# PIC32CK2051GC01064 register map
Vendor: Microchip Technology; Series: PIC32CKGC01; File version: 0
CPU: CM33 r0p0, little endian, MPU, FPU, DSP, 3 interrupt priority bits, 158 interrupts
Registers are 32-bit, read-write, reset 0x0 unless marked. A register's access mark holds for its fields unless they carry their own. Offsets are from the block's base; [hi:lo] are bit positions; {n}, {i} and the like mark numbered series.

## CoreDebug — Debug Control Block
Base 0xE000EDF0
0x00 DHCSR — Debug Halting Control and Status Register
  [26] S_RESTART_ST ro — Restart sticky status
  [25] S_RESET_ST ro — Reset sticky status
  [24] S_RETIRE_ST ro — Retire sticky status
  [23] S_FPD ro — Floating-point registers Debuggable
  [22] S_SUIDE ro — Secure unprivileged-only halting debug enabled
  [21] S_NSUIDE ro — Non-secure unprivileged-only haltingdebug enabled
  [20] S_SDE ro — Secure debug enabled
  [19] S_LOCKUP ro — Lockup status
  [18] S_SLEEP ro — Sleeping status
  [17] S_HALT ro — Halted status
  [16] S_REGRDY ro — Register ready status
  [31:16] DBGKEY wo — Debug key, must write 0xA05F to enable writes
  [6] C_PMOV — Halt on PMU overflow contro
  [5] C_SNAPSTALL — Snap stall control
  [3] C_MASKINTS — Mask PendSV, SysTick and external configurable interrupts
  [2] C_STEP — Enable single step
  [1] C_HALT — Halt processor
  [0] C_DEBUGEN — Enable Halting debug
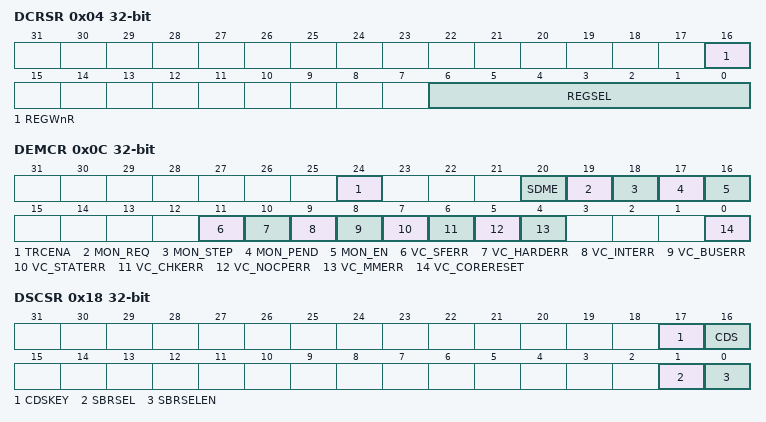
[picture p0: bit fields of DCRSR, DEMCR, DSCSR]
0x04 DCRSR wo — Debug Core Register Select Register
  [16] REGWnR — Register write/not-read access
  [6:0] REGSEL — Register selector
0x08 DCRDR — Debug Core Register Data Register
  [31:0] DBGTMP — Data temporary buffer
0x0C DEMCR — Debug Exception and Monitor Control Register
  [24] TRCENA — Global DWT and ITM features enable
  [20] SDME — Secure DebugMonitor enable
  [19] MON_REQ — DebugMonitor semaphore bit
  [18] MON_STEP — Enable DebugMonitor stepping
  [17] MON_PEND — DebugMonitor pending state
  [16] MON_EN — DebugMonitor enable
  [11] VC_SFERR — SecureFault exception Halting debug vector catch enable
  [10] VC_HARDERR — HardFault exception Halting debug vector catch enable
  [9] VC_INTERR — Exception entry and return faults Halting debug vector catch enable
  [8] VC_BUSERR — BusFault exception Halting debug vector catch enable
  [7] VC_STATERR — UsageFault exception state information error Halting debug vector catch enable
  [6] VC_CHKERR — UsageFault exception checking error Halting debug vector catch enable
  [5] VC_NOCPERR — UsageFault exception coprocessor access Halting debug vector catch enable
  [4] VC_MMERR — MemManage exception Halting debug vector catch enable
  [0] VC_CORERESET — Core reset Halting debug vector catch enable
0x18 DSCSR — Debug Security Control and Status Register
  [17] CDSKEY — CDS field write-enable key
  [16] CDS — Current domain Secure
  [1] SBRSEL — Secure Banked register select
  [0] SBRSELEN — Secure Banked register select enable

## DIB — Debug Identification Block
Base 0xE000EFB0
0x00 DLAR wo — SCS Software Lock Access Register
  [31:0] KEY — Lock access control
    0xC5ACCE55=UNLOCK (Unlock key value)
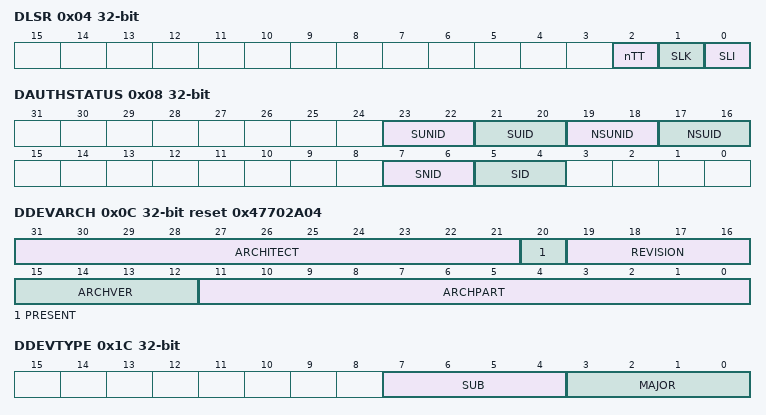
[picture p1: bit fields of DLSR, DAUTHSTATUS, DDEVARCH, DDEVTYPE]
0x04 DLSR ro — SCS Software Lock Status Register
  [2] nTT — Not thirty-two bit
  [1] SLK — Software Lock status
  [0] SLI — Software Lock implemented
0x08 DAUTHSTATUS ro — Debug Authentication Status Register
  [23:22] SUNID — Secure Unprivileged Non-invasive Debug
    0=NOSEC (Security Extension or Unprivileged Non-invasive Debug not implemented); 2=NO (Secure Non-invasive debug prohibited); 3=YES (Secure Non-invasive debug allowed in unprivileged mode)
  [21:20] SUID — Secure Unprivileged Invasive Debug
    0=NOSEC (Security Extension or Unprivileged Debug not implemented); 2=NO (Secure halting debug prohibited); 3=YES (Secure halting debug allowed in unprivileged mode)
  [19:18] NSUNID — Non-secure Unprivileged Non-invasive Debug
    0=NOSEC (Unprivileged Non-invasive debug not implemented); 2=NO (Non-secure Non-invasive debug prohibited); 3=YES (Non-secure Non-invasive debug allowed in unprivileged mode)
  [17:16] NSUID — Non-secure Unprivileged Invasive Debug
    0=NOSEC (Unprivileged halting debug not implemented); 2=NO (Non-secure halting debug prohibited); 3=YES (Non-secure halting debug allowed in unprivileged mode)
  [7:6] SNID — Secure Non-invasive Debug
    0=NOSEC (Security Extension not implemented); 2=NO (Secure non-invasive debug prohibited); 3=YES (Secure non-invasive debug allowed)
  [5:4] SID — Secure Invasive Debug
    0=NOSEC (Security Extension not implemented); 2=NO (Secure invasive debug prohibited); 3=YES (Secure invasive debug allowed)
0x0C DDEVARCH ro reset 0x47702A04 — SCS Device Architecture Register
  [31:21] ARCHITECT
  [20] PRESENT — DEVARCH Present
  [19:16] REVISION
  [15:12] ARCHVER — Architecture Version
  [11:0] ARCHPART — Architecture Part
0x1C DDEVTYPE ro — SCS Device Type Register
  [7:4] SUB — Sub-type
  [3:0] MAJOR — Major type
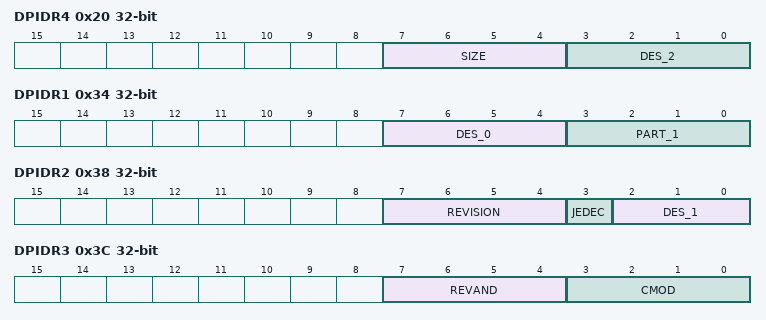
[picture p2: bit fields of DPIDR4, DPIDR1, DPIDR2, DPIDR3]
0x20 DPIDR4 ro — SCS Peripheral Identification Register 4
  [7:4] SIZE — 4KB count
  [3:0] DES_2 — JEP106 continuation code
{0x10+4i} DPIDR{i} ro (i=5..7) — SCS Peripheral Identification Register {i}
0x30 DPIDR0 ro — SCS Peripheral Identification Register 0
  [7:0] PART_0 — Part number bits[7:0]
0x34 DPIDR1 ro — SCS Peripheral Identification Register 1
  [7:4] DES_0 — JEP106 identification code bits [3:0]
  [3:0] PART_1 — Part number bits[11:8]
0x38 DPIDR2 ro — SCS Peripheral Identification Register 2
  [7:4] REVISION — Component revision
  [3] JEDEC — JEDEC assignee value is used
  [2:0] DES_1 — JEP106 identification code bits[6:4]
0x3C DPIDR3 ro — SCS Peripheral Identification Register 3
  [7:4] REVAND
  [3:0] CMOD — Customer Modified
0x40 DCIDR0 ro reset 0xD — SCS Component Identification Register 0
  [7:0] PRMBL_0 — CoreSight component identification preamble
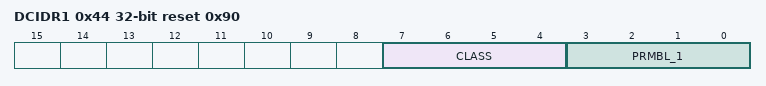
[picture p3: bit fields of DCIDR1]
0x44 DCIDR1 ro reset 0x90 — SCS Component Identification Register 1
  [7:4] CLASS — CoreSight component class
  [3:0] PRMBL_1 — CoreSight component identification preamble
0x48 DCIDR2 ro reset 0x5 — SCS Component Identification Register 2
  [7:0] PRMBL_2 — CoreSight component identification preamble
0x4C DCIDR3 ro reset 0xB1 — SCS Component Identification Register 3
  [7:0] PRMBL_3 — CoreSight component identification preamble

## Notices in the file
Copyright (c) 2026 Microchip Technology Inc.
SPDX-License-Identifier: Apache-2.0
Licensed under the Apache License, Version 2.0 (the "License");
you may not use this file except in compliance with the License.
You may obtain a copy of the License at
http://www.apache.org/licenses/LICENSE-2.0
Unless required by applicable law or agreed to in writing, software
distributed under the License is distributed on an "AS IS" BASIS,
WITHOUT WARRANTIES OR CONDITIONS OF ANY KIND, either express or implied.
See the License for the specific language governing permissions and
limitations under the License.
